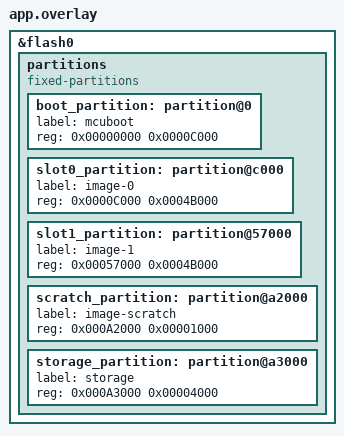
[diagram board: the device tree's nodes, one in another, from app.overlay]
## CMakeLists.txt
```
cmake_minimum_required(VERSION 3.20.0)
find_package(Zephyr REQUIRED HINTS $ENV{ZEPHYR_BASE})
project(remote_motor_fw)

zephyr_include_directories(${CMAKE_CURRENT_SOURCE_DIR}/include)

target_sources(app PRIVATE
  src/main.c
  src/bluetooth/bluetooth.c
  src/simulation/motor_sim.c
  src/watchdog/watchdog.c
  src/motor/motor.c
)
```

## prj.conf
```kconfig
CONFIG_BT=y
CONFIG_BT_PERIPHERAL=y
CONFIG_BT_DEVICE_NAME="MOTORSRV"
CONFIG_BT_GATT_CLIENT=y
CONFIG_BT_EXT_ADV=n

CONFIG_LOG=y
CONFIG_LOG_BUFFER_SIZE=2048
CONFIG_GPIO=y

# Enable console over UART
CONFIG_SERIAL=y
CONFIG_CONSOLE=y
CONFIG_UART_CONSOLE=y

CONFIG_HWINFO=y

# Enable logging system
CONFIG_LOG=y
# 0=off, 1=error, 2=warn, 3=info, 4=debug
CONFIG_LOG_DEFAULT_LEVEL=3
CONFIG_LOG_PRINTK=y
CONFIG_LOG_BACKEND_UART=y
```

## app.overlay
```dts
&flash0{
    /delete-node/ partitions;
    partitions{
        compatible = "fixed-partitions";
        #address-cells = <1>;
        #size-cells = <1>;

        // BOOT PARITION NEED 48KB (0xC000), 32 KB IS LIMIT
        boot_partition: partition@0{
            label = "mcuboot";
            reg = <0x00000000 0x0000C000>;
        };
        
        slot0_partition: partition@c000{
            label = "image-0";
            reg = <0x0000C000 0x0004B000>;
        };

        // SLOT 1 - UPDATE STAGING (WHERE THE NEXT VERSION EXISTS)
        slot1_partition: partition@57000{
            label = "image-1";
            reg = <0x00057000 0x0004B000>;
        };

        // SCRATCH - SWAP WORKSPACE (BETWEEN THE SLOTS)
        scratch_partition: partition@a2000{
            label = "image-scratch";
            reg = <0x000A2000 0x00001000>;
        };

        // STORAGE NVS AND SETTINGS FOR 16KB
        storage_partition: partition@a3000{
            label = "storage";
            reg = <0x000A3000 0x00004000>;
        };
    };
};
```

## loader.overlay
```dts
/* loader.overlay - FORCE BOOTLOADER LOCATION */
/ {
    chosen {
        zephyr,code-partition = &boot_partition;
    };
};
```

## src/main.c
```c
#include <zephyr/types.h>
#include <stddef.h>
#include <string.h>
#include <errno.h>
#include <zephyr/sys/printk.h>
#include <zephyr/kernel.h>
#include <zephyr/drivers/gpio.h>
#include <zephyr/logging/log.h>
#include <zephyr/drivers/hwinfo.h>
#include <stdio.h>

#include "bluetooth.h"
#include "motor_sim.h"
#include "watchdog.h"
#include "motor.h" // Needed for motor_init

LOG_MODULE_REGISTER(main, LOG_LEVEL_INF);

int main(void)
{
    LOG_INF("Starting Bluetooth Motor Control Application");    

    // 1. Initialize the Motor Data Structures (Safe API)
    motor_init(); 

    // 2. Initialize Bluetooth
    int err = bt_enable(bt_ready);
    if (err) {
        LOG_ERR("Bluetooth init failed (err %d)", err);
        return 0;
    }

    // 3. Register Callbacks & Start Watchdog
    bt_conn_cb_register(&conn_callbacks);
    watchdog_init();

    // 4. Start the Physics Simulation
    motor_sim_init();

    return 0;
}
```

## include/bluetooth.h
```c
#ifndef BLUETOOTH_H_
#define BLUETOOTH_H_

#include <zephyr/types.h>
#include <zephyr/bluetooth/bluetooth.h>
#include <zephyr/bluetooth/conn.h>
#include <zephyr/bluetooth/gatt.h>
#include <zephyr/bluetooth/uuid.h>
#include <zephyr/logging/log.h>

#define MY_COMPANY_ID 0x706D

// MOTOR SERVICE UUID
#define BT_UUID_MOTOR_SERVICE_VAL \
	BT_UUID_128_ENCODE(0xc52081ba, 0xe90f, 0x40e4, 0xa99f, 0xccaa4fd11c15)

// COMMAND CHARACTERISTIC UUID
#define BT_UUID_MOTOR_CMD_VAL \
	BT_UUID_128_ENCODE(0xd10b46cd, 0x412a, 0x4d15, 0xa7bb, 0x092a329eed46)

// MOTOR TELEMETRY UUID
#define BT_UUID_MOTOR_TELEMETRY_VAL \
	BT_UUID_128_ENCODE(0x17da15e5, 0x05b1, 0x42df, 0x8d9d, 0xd7645d6d9293)

// MOTOR HEARTBEAT UUID
#define BT_UUID_MOTOR_HEARTBEAT_VAL \
	BT_UUID_128_ENCODE(0x2215d558, 0xc569, 0x4bd1, 0x8947, 0xb4fd5f9432a0)


enum motor_cmds{
	MOTOR_MODE_OFF = 0x00,
	MOTOR_MODE_INIT = 0x01,
	MOTOR_MODE_SPEED = 0x02,
	MOTOR_MODE_POSITION = 0x03
};

// MOTOR APPLICATION DATA STRUCTURE
struct motor_app_ctx{
	// FLAG TO INDICATE IF NOTIFICATIONS ARE ENABLED FOR USER
	bool notification_enabled; 
	
	// HEARTBEAT VALUE -> CONFIRMS BLE SYNCHRONIZATION
	uint8_t heartbeat_val;
};

// PUBLIC API GETTERS FOR BLUETOOTH STATS

/** @brief Get the latest heartbeat counter value (received from the phone via BLE)*/
uint8_t bt_get_heartbeat(void);
/** @brief Check if the android device has subscribed to notifications*/
uint8_t bt_is_notify_enabled(void);

void bt_ready(int err);

void motor_notify_telemetry(void);

// MAIN.c has to register the bluetooth
extern struct bt_conn_cb conn_callbacks;

#endif /* BLUETOOTH_H_ */
```

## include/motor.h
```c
#ifndef MOTOR_H_
#define MOTOR_H_

#include <zephyr/types.h>
#include <stdbool.h>

#define RPM_MAX     6000
#define RPM_MIN     -6000

// MOTOR STATUS ARCHITECTURE

// LOWER NIBBLE: MUTUALLY EXCLUSIVE MOTOR STATES (BITS 0-3) - WHAT IS THE MOTOR DOING (THIS IS THE ACTUAL TRUE STATE OF THE MOTOR)
#define MOTOR_STATE_STOPPED			0x00	// 0000
#define MOTOR_STATE_RUNNING_SPEED	0x01	// 0001 - MOTOR IS ATTEMPTING TO REACH A CERTAIN RPM
#define MOTOR_STATE_RUNNING_POS		0x02	// 0010 - MOTOR IS ATTEMPTING TO REACH A CERTAIN POS
#define MOTOR_STATE_ESTOP			0x03	// 0010 (EMERGENCY STOP)
#define MOTOR_STATE_RESTART			0x04	// 0100 (SOFT START/CALIBRATING)
#define MOTOR_STATE_FAULT			0x05	// 0101 (HARDWARE FAILURE)

#define MOTOR_STATE_MASK			0x0F	// 0000 1111 (ISOLATE THE MOTOR STATE)

// UPPER NIBBLE: DIAGNOSTIC FLAGS (BITS 4-7) - CHECK IF THERE ARE ANY WARNINGS/ISSUES REGARDING THE MOTOR
#define MOTOR_FLAG_SYNC_BAD			0x10	// 0001 0000 
#define MOTOR_FLAG_OVERHEAT			0x20	// 0010 0000

#define MOTOR_FLAG_MASK				0xF0	// 1111 0000 - ISOLATE FLAGS


struct motor_stats{

	// SET POINTS - TARGETED VALUES FOR THE MOTOR
	uint8_t target_state;		// STATE THAT WE WANT THE MOTOR TO BE IN
	int32_t target_speed;		// REQUESTED RPM
	int32_t target_position;	// REQUESTED ANGLE

	// ACTUAL MOTOR STATS - FEEDBACK FROM THE HARDWARE, ACTUAL READINGS
	// STATUS OF MOTOR [FLAGS (4 bits) | STATE (4-bits)]
	uint8_t motor_status;

	// CURRENT SPEED OF MOTOR (RPM)
	int32_t current_speed;

	// CURRENT POSITION OF MOTOR (Degrees)
	int32_t current_position;
};


// PUBLIC API - MOTOR CONTROL
/** @brief Initialize motor hardware and clear stats */
void motor_init(void);

// ACTUAL MOTOR STAT SETTERS
/** @brief SET THE MOTOR'S RPM (THIS IS THE ACTUAL & TRUE VALUE OF THE MOTOR) */
void motor_set_speed(int32_t rpm);

/** @brief SET THE MOTOR'S POSITION (THIS IS THE ACTUAL VALUE OF THE MOTOR) */
void motor_set_position(int32_t degrees);

/** @brief Update the motor's internal state (keep flags) */
void motor_set_state(uint8_t new_state);

/** @brief SET OR CLEAR SPECIFIC DIAGONISTIC FLAGS */
void motor_set_flag(uint8_t flag, bool active);

void motor_set_sync_warning(bool active);
void motor_set_overheat_warning(bool active);

// TARGETED SETTERS
/** @brief SET THE TARGETED/DESIRED MOTOR STATE - ONLY THE LOWER NIBBLES (NO FLAGS)*/
void motor_set_target_state(uint8_t new_state);

/** @brief SET THE DESIRED MOTOR RPM (STILL NEED TO SET THE TARGET STATE)) */
void motor_set_target_speed(int32_t rpm);

/** @brief SET THE DESIRED MOTOR POSITION (STILL NEED TO SET THE TARGET STATE) */
void motor_set_target_position(int32_t degrees);



// PUBLIC API - GETTERS

// ACTUAL MOTOR STAT GETTERS
// STATUS
uint8_t motor_get_full_status(void);
bool motor_is_sync_bad(void);
bool motor_is_overheated(void);
// TELEMETRY
int32_t motor_get_speed(void);
int32_t motor_get_position(void);

// TARGETED MOTOR STAT GETTERS
uint8_t motor_get_target_state(void);
int32_t motor_get_target_speed(void);
int32_t motor_get_target_position(void);

#endif
```

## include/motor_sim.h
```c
#ifndef MOTOR_SIM_H_
#define MOTOR_SIM_H_

/** @brief Initialize and start the motor simulation thread */
void motor_sim_init(void);

#endif /* MOTOR_SIM_H_ */
```
